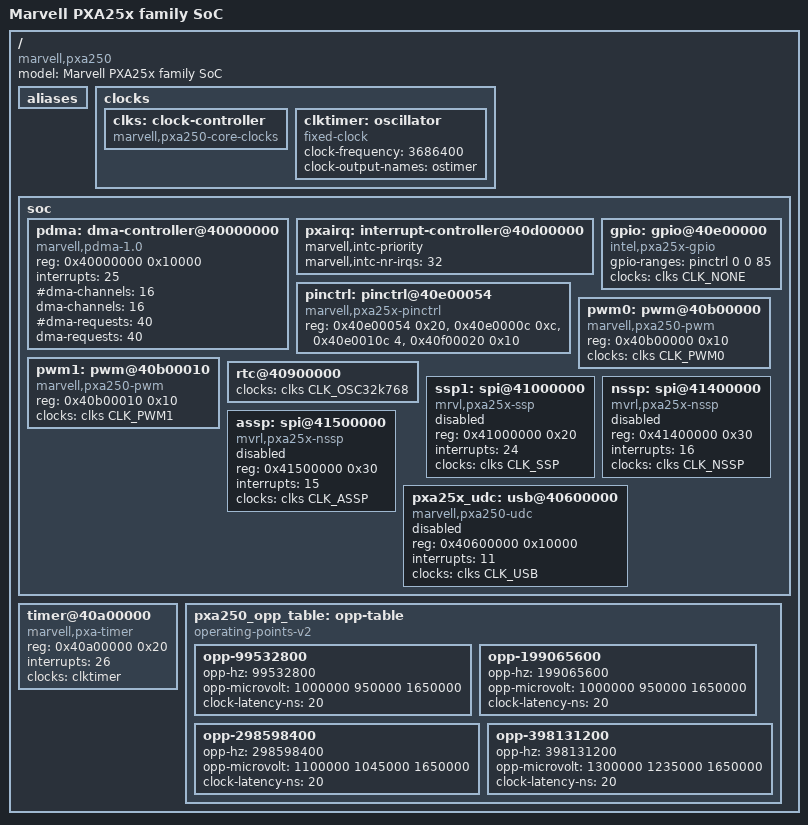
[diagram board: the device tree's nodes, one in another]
// SPDX-License-Identifier: GPL-2.0-or-later
/*
 * Copyright (C) 2016 Robert Jarzmik <robert.jarzmik@free.fr>
 */
#include "pxa2xx.dtsi"
#include "dt-bindings/clock/pxa-clock.h"

/ {
	model = "Marvell PXA25x family SoC";
	compatible = "marvell,pxa250";

	/*
	 * Unlike PXA27x/PXA3xx, PXA25x has no power-I2C block, so the
	 * "i2c0 = &pwri2c" alias inherited from pxa2xx.dtsi points at a
	 * node this variant never defines. Drop it here rather than in
	 * the shared file so PXA27x/PXA3xx keep it.
	 */
	aliases {
		/delete-property/ i2c0;
	};

	clocks {
	       /*
		* The muxing of external clocks/internal dividers for osc* clock
		* sources has been hidden under the carpet by now.
		*/
		#address-cells = <1>;
		#size-cells = <1>;
		ranges;

		clks: clock-controller {
			compatible = "marvell,pxa250-core-clocks";
			#clock-cells = <1>;
			status = "okay";
		};

		/* timer oscillator */
		clktimer: oscillator {
			compatible = "fixed-clock";
			#clock-cells = <0>;
			clock-frequency  = <3686400>;
			clock-output-names = "ostimer";
		};
	};

	soc {
		pdma: dma-controller@40000000 {
			compatible = "marvell,pdma-1.0";
			reg = <0x40000000 0x10000>;
			interrupts = <25>;
			#dma-cells = <2>;
			/* For backwards compatibility: */
			#dma-channels = <16>;
			dma-channels = <16>;
			#dma-requests = <40>;
			dma-requests = <40>;
			status = "okay";
		};

		pxairq: interrupt-controller@40d00000 {
			marvell,intc-priority;
			marvell,intc-nr-irqs = <32>;
		};

		pinctrl: pinctrl@40e00054 {
			reg = <0x40e00054 0x20>, <0x40e0000c 0xc>, <0x40e0010c 4>,
			      <0x40f00020 0x10>;
			compatible = "marvell,pxa25x-pinctrl";
		};

		gpio: gpio@40e00000 {
			compatible = "intel,pxa25x-gpio";
			gpio-ranges = <&pinctrl 0 0 85>;
			clocks = <&clks CLK_NONE>;
		};

		pwm0: pwm@40b00000 {
			compatible = "marvell,pxa250-pwm";
			reg = <0x40b00000 0x10>;
			#pwm-cells = <1>;
			clocks = <&clks CLK_PWM0>;
		};

		pwm1: pwm@40b00010 {
			compatible = "marvell,pxa250-pwm";
			reg = <0x40b00010 0x10>;
			#pwm-cells = <1>;
			clocks = <&clks CLK_PWM1>;
		};

		rtc@40900000 {
			clocks = <&clks CLK_OSC32k768>;
		};

		/*
		 * PXA25x has three distinct SSP-family blocks rather than
		 * three instances of one type: the primary SSP is present on
		 * every chip, NSSP and ASSP only on PXA255/26x. The primary
		 * unit has a 0x20 byte window and uses CLK_SSP, not CLK_SSP1.
		 * ASSP is equivalent to NSSP and shares its compatible string,
		 * which carries the "mvrl" spelling matched by
		 * drivers/soc/pxa/ssp.c and marvell,mmp2-ssp.yaml.
		 *
		 * All three are left disabled: a board enables and gives a role
		 * to the instance it wires up.
		 */
		ssp1: spi@41000000 {
			compatible = "mrvl,pxa25x-ssp";
			reg = <0x41000000 0x20>;
			interrupts = <24>;
			clocks = <&clks CLK_SSP>;
			status = "disabled";
		};

		nssp: spi@41400000 {
			compatible = "mvrl,pxa25x-nssp";
			reg = <0x41400000 0x30>;
			interrupts = <16>;
			clocks = <&clks CLK_NSSP>;
			status = "disabled";
		};

		assp: spi@41500000 {
			compatible = "mvrl,pxa25x-nssp";
			reg = <0x41500000 0x30>;
			interrupts = <15>;
			clocks = <&clks CLK_ASSP>;
			status = "disabled";
		};

		pxa25x_udc: usb@40600000 {
			compatible = "marvell,pxa250-udc";
			reg = <0x40600000 0x10000>;
			interrupts = <11>;
			clocks = <&clks CLK_USB>;
			status = "disabled";
		};
	};

	timer@40a00000 {
		compatible = "marvell,pxa-timer";
		reg = <0x40a00000 0x20>;
		interrupts = <26>;
		clocks = <&clktimer>;
		status = "okay";
	};

	pxa250_opp_table: opp-table {
		compatible = "operating-points-v2";

		opp-99532800 {
			opp-hz = /bits/ 64 <99532800>;
			opp-microvolt = <1000000 950000 1650000>;
			clock-latency-ns = <20>;
		};
		opp-199065600 {
			opp-hz = /bits/ 64 <199065600>;
			opp-microvolt = <1000000 950000 1650000>;
			clock-latency-ns = <20>;
		};
		opp-298598400 {
			opp-hz = /bits/ 64 <298598400>;
			opp-microvolt = <1100000 1045000 1650000>;
			clock-latency-ns = <20>;
		};
		opp-398131200 {
			opp-hz = /bits/ 64 <398131200>;
			opp-microvolt = <1300000 1235000 1650000>;
			clock-latency-ns = <20>;
		};
	};
};
